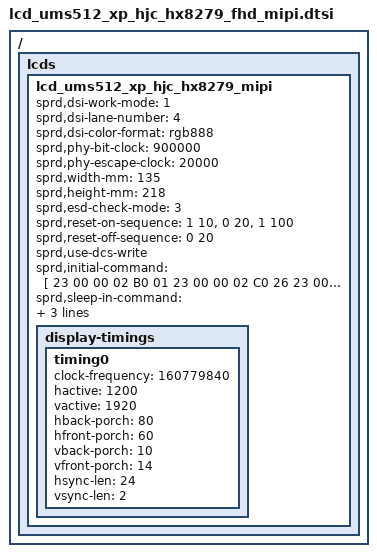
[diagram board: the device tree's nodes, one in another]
/ { lcds {
	lcd_ums512_xp_hjc_hx8279_mipi: lcd_ums512_xp_hjc_hx8279_mipi {

		sprd,dsi-work-mode = <1>; /* video burst mode*/
		sprd,dsi-lane-number = <4>;
		sprd,dsi-color-format = "rgb888";

		sprd,phy-bit-clock = <900000>;  /* kbps */
		sprd,phy-escape-clock = <20000>;/* kHz */

		sprd,width-mm = <135>;
		sprd,height-mm = <218>;

		sprd,esd-check-mode = <3>;

		sprd,reset-on-sequence = <1 10>, <0 20>, <1 100>;
		sprd,reset-off-sequence = <0 20>;

		sprd,use-dcs-write;

		sprd,initial-command = [
		  23 00 00 02 B0 01 	
	  23 00 00 02 C0 26 	
	  23 00 00 02 C1 10 	
	  23 00 00 02 C2 0E 	
	  23 00 00 02 C3 00 	
	  23 00 00 02 C4 00 	
	  23 00 00 02 C5 23 	
	  23 00 00 02 C6 11 	
	  23 00 00 02 C7 22 	
	  23 00 00 02 C8 20 	
	  23 00 00 02 C9 1E 	
	  23 00 00 02 CA 1C 	
	  23 00 00 02 CB 0C 	
	  23 00 00 02 CC 0A 	
	  23 00 00 02 CD 08 	
	  23 00 00 02 CE 06 	
	  23 00 00 02 CF 18 	
	  23 00 00 02 D0 02 	
	  23 00 00 02 D1 00 	
	  23 00 00 02 D2 00 	
	  23 00 00 02 D3 00 	
	  23 00 00 02 D4 26 	
	  23 00 00 02 D5 0F 	
	  23 00 00 02 D6 0D 	
	  23 00 00 02 D7 00 	
	  23 00 00 02 D8 00 	
	  23 00 00 02 D9 23 	
	  23 00 00 02 DA 11 	
	  23 00 00 02 DB 21 	
	  23 00 00 02 DC 1F 	
	  23 00 00 02 DD 1D 	
	  23 00 00 02 DE 1B 	
	  23 00 00 02 DF 0B 	
	  23 00 00 02 E0 09 	
	  23 00 00 02 E1 07 	
	  23 00 00 02 E2 05 	
	  23 00 00 02 E3 17 	
	  23 00 00 02 E4 01 	
	  23 00 00 02 E5 00 	
	  23 00 00 02 E6 00 	
	  23 00 00 02 E7 00 	
	  23 00 00 02 B0 03 	
	  23 00 00 02 BE 04 	
	  23 00 00 02 B9 40 	
	  23 00 00 02 CC 88 	
	  23 00 00 02 C8 0C 	
	  23 00 00 02 C9 07 	
	  23 00 00 02 CD 01 	
	  23 00 00 02 CA 40 	
	  23 00 00 02 CE 1A 	
	  23 00 00 02 CF 60 	
	  23 00 00 02 D2 08 	
	  23 00 00 02 D3 08 	
	  23 00 00 02 DB 01 	
	  23 00 00 02 D9 06 	
	  23 00 00 02 D4 00 	
	  23 00 00 02 D5 01 	
	  23 00 00 02 D6 04 	
	  23 00 00 02 D7 03 	
	  23 00 00 02 C2 00 	
	  23 00 00 02 C3 0E 	
	  23 00 00 02 C4 00 	
	  23 00 00 02 C5 0E 	
	  23 00 00 02 DD 00 	
	  23 00 00 02 DE 0E 	
	  23 00 00 02 E6 00 	
	  23 00 00 02 E7 0E 	
	  23 00 00 02 C2 00 	
	  23 00 00 02 C3 0E 	
	  23 00 00 02 C4 00 	
	  23 00 00 02 C5 0E 	
	  23 00 00 02 DD 00 	
	  23 00 00 02 DE 0E 	
	  23 00 00 02 E6 00 	
	  23 00 00 02 E7 0E 	
	  23 00 00 02 B0 06 	
	  23 00 00 02 C0 A5 	
	  23 00 00 02 D5 1C 	
	  23 00 00 02 C0 00 	
	  23 00 00 02 B0 00 
	  23 00 00 02 BD 30 //VCOM	  37
		
	  23 00 00 02 F9 5C 	
	  23 00 00 02 C2 14 	
	  23 00 00 02 C4 14 	
	  23 00 00 02 BF 15 	
	  23 00 00 02 C0 0C 	


	  23 00 00 02 B0 00 
	  23 00 00 02 B1 79 
	  23 00 00 02 BA 8E //
 
	 23 78 00 02 11 00 
	 23 05 00 02 29 00 
	//--- TE----//
	// 23 00 00 02 35 00 	

			];

		sprd,sleep-in-command = [
			13 0A 00 01 28
			13 78 00 01 10
			];
		sprd,sleep-out-command = [
			  23 00 00 02 B0 01 	
			  23 00 00 02 C0 26 	
			  23 00 00 02 C1 10 	
			  23 00 00 02 C2 0E 	
			  23 00 00 02 C3 00 	
			  23 00 00 02 C4 00 	
			  23 00 00 02 C5 23 	
			  23 00 00 02 C6 11 	
			  23 00 00 02 C7 22 	
			  23 00 00 02 C8 20 	
			  23 00 00 02 C9 1E 	
			  23 00 00 02 CA 1C 	
			  23 00 00 02 CB 0C 	
			  23 00 00 02 CC 0A 	
			  23 00 00 02 CD 08 	
			  23 00 00 02 CE 06 	
			  23 00 00 02 CF 18 	
			  23 00 00 02 D0 02 	
			  23 00 00 02 D1 00 	
			  23 00 00 02 D2 00 	
			  23 00 00 02 D3 00 	
			  23 00 00 02 D4 26 	
			  23 00 00 02 D5 0F 	
			  23 00 00 02 D6 0D 	
			  23 00 00 02 D7 00 	
			  23 00 00 02 D8 00 	
			  23 00 00 02 D9 23 	
			  23 00 00 02 DA 11 	
			  23 00 00 02 DB 21 	
			  23 00 00 02 DC 1F 	
			  23 00 00 02 DD 1D 	
			  23 00 00 02 DE 1B 	
			  23 00 00 02 DF 0B 	
			  23 00 00 02 E0 09 	
			  23 00 00 02 E1 07 	
			  23 00 00 02 E2 05 	
			  23 00 00 02 E3 17 	
			  23 00 00 02 E4 01 	
			  23 00 00 02 E5 00 	
			  23 00 00 02 E6 00 	
			  23 00 00 02 E7 00 	
			  23 00 00 02 B0 03 	
			  23 00 00 02 BE 04 	
			  23 00 00 02 B9 40 	
			  23 00 00 02 CC 88 	
			  23 00 00 02 C8 0C 	
			  23 00 00 02 C9 07 	
			  23 00 00 02 CD 01 	
			  23 00 00 02 CA 40 	
			  23 00 00 02 CE 1A 	
			  23 00 00 02 CF 60 	
			  23 00 00 02 D2 08 	
			  23 00 00 02 D3 08 	
			  23 00 00 02 DB 01 	
			  23 00 00 02 D9 06 	
			  23 00 00 02 D4 00 	
			  23 00 00 02 D5 01 	
			  23 00 00 02 D6 04 	
			  23 00 00 02 D7 03 	
			  23 00 00 02 C2 00 	
			  23 00 00 02 C3 0E 	
			  23 00 00 02 C4 00 	
			  23 00 00 02 C5 0E 	
			  23 00 00 02 DD 00 	
			  23 00 00 02 DE 0E 	
			  23 00 00 02 E6 00 	
			  23 00 00 02 E7 0E 	
			  23 00 00 02 C2 00 	
			  23 00 00 02 C3 0E 	
			  23 00 00 02 C4 00 	
			  23 00 00 02 C5 0E 	
			  23 00 00 02 DD 00 	
			  23 00 00 02 DE 0E 	
			  23 00 00 02 E6 00 	
			  23 00 00 02 E7 0E 	
			  23 00 00 02 B0 06 	
			  23 00 00 02 C0 A5 	
			  23 00 00 02 D5 1C 	
			  23 00 00 02 C0 00 	
			  23 00 00 02 B0 00 
			  23 00 00 02 BD 30 //VCOM	  37
		
			  23 00 00 02 F9 5C 	
			  23 00 00 02 C2 14 	
			  23 00 00 02 C4 14 	
			  23 00 00 02 BF 15 	
			  23 00 00 02 C0 0C 	


			  23 00 00 02 B0 00 
			  23 00 00 02 B1 79 
			  23 00 00 02 BA 8E //
 
			 23 78 00 02 11 00 
			 23 05 00 02 29 00 
			//--- TE----//
			// 23 00 00 02 35 00 				
	];

		display-timings {
			timing0 {
				clock-frequency = <160779840>;
				hactive = <1200>;
				vactive = <1920>;
				hback-porch = <80>;
				hfront-porch = <60>;
				vback-porch = <10>;
				vfront-porch = <14>;
				hsync-len = <24>;
				vsync-len = <2>;
			};
		};
	};
};};
